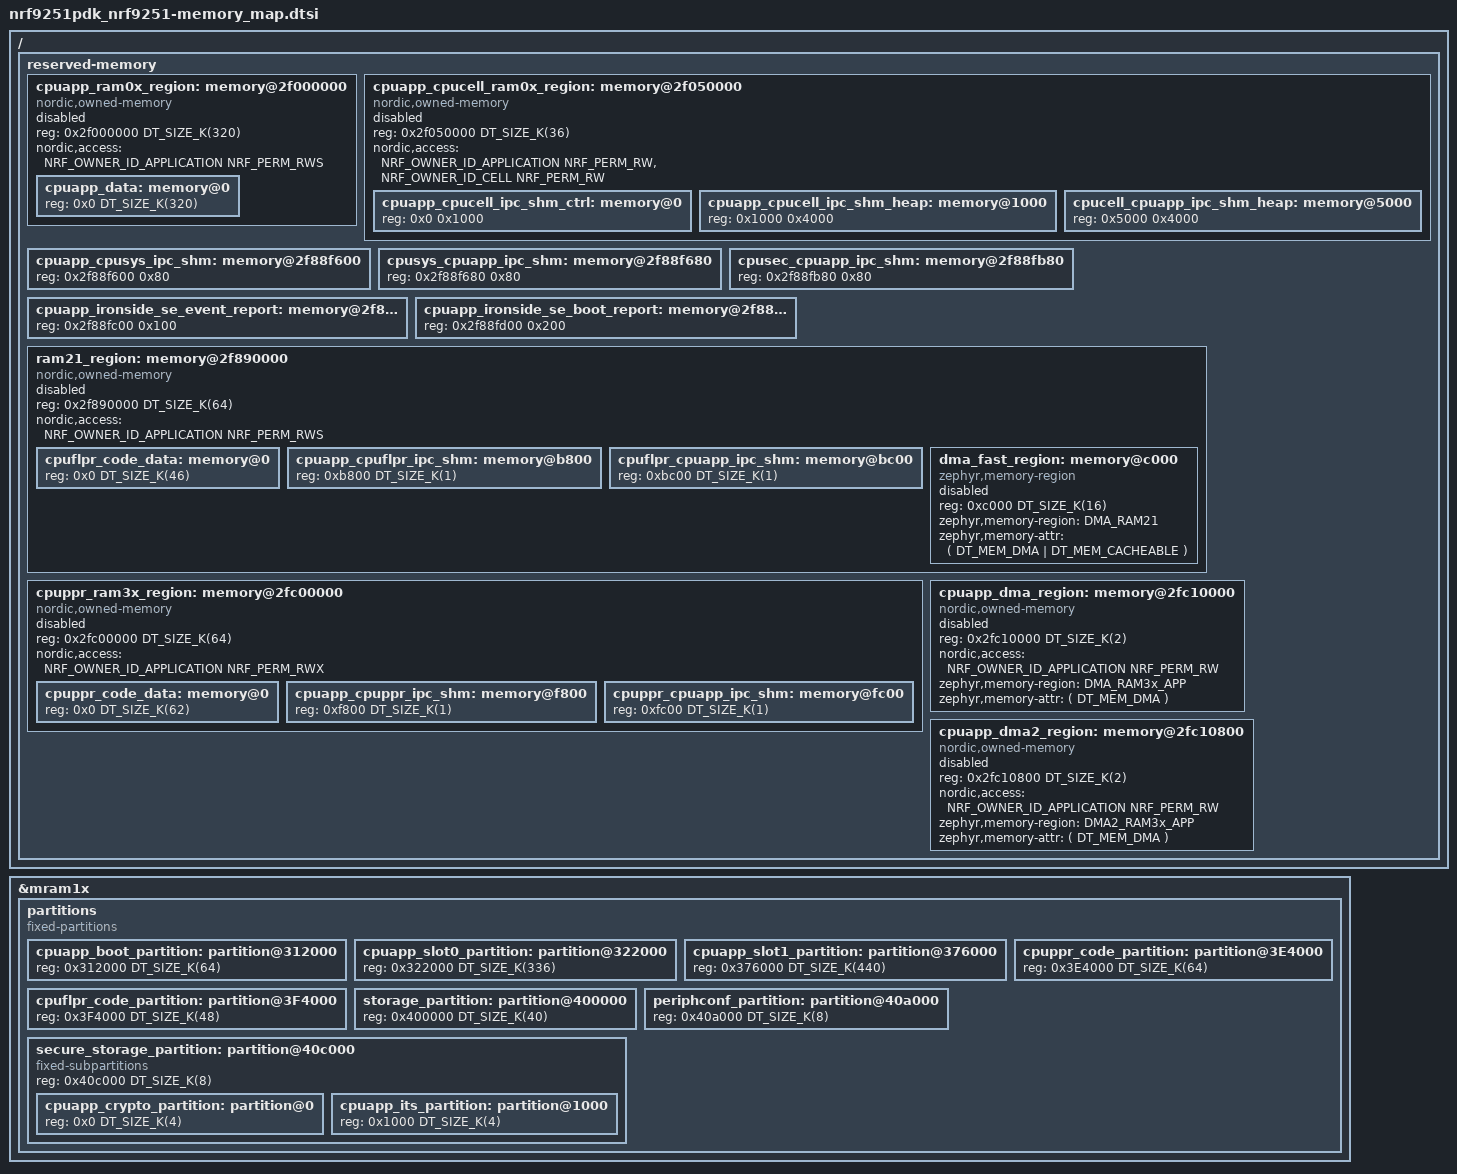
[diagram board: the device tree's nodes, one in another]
/*
 * Copyright (c) 2026 Nordic Semiconductor ASA
 *
 * SPDX-License-Identifier: Apache-2.0
 */

#include <zephyr/dt-bindings/memory-attr/memory-attr.h>
#include <zephyr/dt-bindings/reserved-memory/nordic-owned-memory.h>

/ {
	reserved-memory {
		#address-cells = <1>;
		#size-cells = <1>;

		cpuapp_ram0x_region: memory@2f000000 {
			compatible = "nordic,owned-memory";
			reg = <0x2f000000 DT_SIZE_K(320)>;
			status = "disabled";
			nordic,access = <NRF_OWNER_ID_APPLICATION NRF_PERM_RWS>;
			#address-cells = <1>;
			#size-cells = <1>;
			ranges = <0x0 0x2f000000 0x50000>;

			cpuapp_data: memory@0 {
				reg = <0x0 DT_SIZE_K(320)>;
			};
		};

		cpuapp_cpucell_ram0x_region: memory@2f050000 {
			compatible = "nordic,owned-memory";
			reg = <0x2f050000 DT_SIZE_K(36)>;
			status = "disabled";
			nordic,access = <NRF_OWNER_ID_APPLICATION NRF_PERM_RW>,
					<NRF_OWNER_ID_CELL NRF_PERM_RW>;
			#address-cells = <1>;
			#size-cells = <1>;
			ranges = <0x0 0x2f050000 0x9000>;

			/* Control region, with ICmsg buffers.
			 * Size is fixed.
			 */
			cpuapp_cpucell_ipc_shm_ctrl: memory@0 {
				reg = <0x0 0x1000>;
			};

			/* TX heap, user defined */
			cpuapp_cpucell_ipc_shm_heap: memory@1000 {
				reg = <0x1000 0x4000>;
			};

			/* RX heap, user defined */
			cpucell_cpuapp_ipc_shm_heap: memory@5000 {
				reg = <0x5000 0x4000>;
			};
		};

		cpuapp_cpusys_ipc_shm: memory@2f88f600 {
			reg = <0x2f88f600 0x80>;
		};

		cpusys_cpuapp_ipc_shm: memory@2f88f680 {
			reg = <0x2f88f680 0x80>;
		};

		cpusec_cpuapp_ipc_shm: memory@2f88fb80 {
			reg = <0x2f88fb80 0x80>;
		};

		cpuapp_ironside_se_event_report: memory@2f88fc00 {
			reg = <0x2f88fc00 0x100>;
		};

		cpuapp_ironside_se_boot_report: memory@2f88fd00 {
			reg = <0x2f88fd00 0x200>;
		};

		ram21_region: memory@2f890000 {
			compatible = "nordic,owned-memory";
			status = "disabled";
			reg = <0x2f890000 DT_SIZE_K(64)>;
			nordic,access = <NRF_OWNER_ID_APPLICATION NRF_PERM_RWS>;
			#address-cells = <1>;
			#size-cells = <1>;
			ranges = <0x0 0x2f890000 0x10000>;

			cpuflpr_code_data: memory@0 {
				reg = <0x0 DT_SIZE_K(46)>;
			};

			cpuapp_cpuflpr_ipc_shm: memory@b800 {
				reg = <0xb800 DT_SIZE_K(1)>;
			};

			cpuflpr_cpuapp_ipc_shm: memory@bc00 {
				reg = <0xbc00 DT_SIZE_K(1)>;
			};

			dma_fast_region: memory@c000 {
				compatible = "zephyr,memory-region";
				reg = <0xc000 DT_SIZE_K(16)>;
				status = "disabled";
				#memory-region-cells = <0>;
				zephyr,memory-region = "DMA_RAM21";
				zephyr,memory-attr = <( DT_MEM_DMA | DT_MEM_CACHEABLE )>;
			};
		};

		cpuppr_ram3x_region: memory@2fc00000 {
			compatible = "nordic,owned-memory";
			reg = <0x2fc00000 DT_SIZE_K(64)>;
			status = "disabled";
			nordic,access = <NRF_OWNER_ID_APPLICATION NRF_PERM_RWX>;
			#address-cells = <1>;
			#size-cells = <1>;
			ranges = <0x0 0x2fc00000 0x10000>;

			cpuppr_code_data: memory@0 {
				reg = <0x0 DT_SIZE_K(62)>;
			};

			cpuapp_cpuppr_ipc_shm: memory@f800 {
				reg = <0xf800 DT_SIZE_K(1)>;
			};

			cpuppr_cpuapp_ipc_shm: memory@fc00 {
				reg = <0xfc00 DT_SIZE_K(1)>;
			};
		};

		cpuapp_dma_region: memory@2fc10000 {
			compatible = "nordic,owned-memory", "zephyr,memory-region";
			reg = <0x2fc10000 DT_SIZE_K(2)>;
			status = "disabled";
			#memory-region-cells = <0>;
			nordic,access = <NRF_OWNER_ID_APPLICATION NRF_PERM_RW>;
			zephyr,memory-region = "DMA_RAM3x_APP";
			zephyr,memory-attr = <( DT_MEM_DMA )>;
		};

		cpuapp_dma2_region: memory@2fc10800 {
			compatible = "nordic,owned-memory", "zephyr,memory-region";
			reg = <0x2fc10800 DT_SIZE_K(2)>;
			status = "disabled";
			#memory-region-cells = <0>;
			nordic,access = <NRF_OWNER_ID_APPLICATION NRF_PERM_RW>;
			zephyr,memory-region = "DMA2_RAM3x_APP";
			zephyr,memory-attr = <( DT_MEM_DMA )>;
		};
	};
};

&mram1x {
	partitions {
		compatible = "fixed-partitions";
		#address-cells = <1>;
		#size-cells = <1>;
		ranges;

		cpuapp_boot_partition: partition@312000 {
			reg = <0x312000 DT_SIZE_K(64)>;
		};

		cpuapp_slot0_partition: partition@322000 {
			reg = <0x322000 DT_SIZE_K(336)>;
		};

		cpuapp_slot1_partition: partition@376000 {
			reg = <0x376000 DT_SIZE_K(440)>;
		};

		cpuppr_code_partition: partition@3E4000 {
			reg = <0x3E4000 DT_SIZE_K(64)>;
		};

		cpuflpr_code_partition: partition@3F4000 {
			reg = <0x3F4000 DT_SIZE_K(48)>;
		};

		storage_partition: partition@400000 {
			reg = <0x400000 DT_SIZE_K(40)>;
		};

		periphconf_partition: partition@40a000 {
			reg = <0x40a000 DT_SIZE_K(8)>;
		};

		secure_storage_partition: partition@40c000 {
			compatible = "fixed-subpartitions";
			reg = <0x40c000 DT_SIZE_K(8)>;
			ranges = <0x0 0x40c000 0x2000>;
			#address-cells = <1>;
			#size-cells = <1>;

			cpuapp_crypto_partition: partition@0 {
				reg = <0x0 DT_SIZE_K(4)>;
			};

			cpuapp_its_partition: partition@1000 {
				reg = <0x1000 DT_SIZE_K(4)>;
			};
		};
	};
};

